VERSION ""

NS_ :

BS_:

BU_:

BO_ 1073 LKAS_ob06_10: 6 Vector__XXX
 SG_ ob_LKA_Disable_Reason : 55|16@0+ (0.01,0) [0|0] "" Vector__XXX
 SG_ ob_LKA_T1_Mon : 39|16@0- (0.01,0) [-327.68|327.67] "" Vector__XXX
 SG_ ob_LKA_SampleTime_Mon : 23|16@0- (0.01,0) [-327.68|327.67] "" Vector__XXX
 SG_ ob_LKA_ExitFlg_Mon : 7|16@0+ (0.01,0) [0|0] "" Vector__XXX

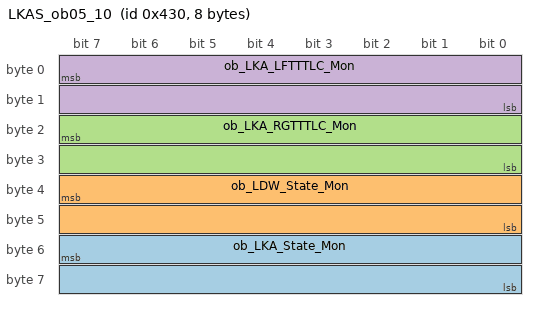
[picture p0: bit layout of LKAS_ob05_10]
BO_ 1072 LKAS_ob05_10: 8 Vector__XXX
 SG_ ob_LKA_State_Mon : 55|16@0+ (0.01,0) [0|0] "" Vector__XXX
 SG_ ob_LDW_State_Mon : 39|16@0+ (0.01,0) [0|0] "" Vector__XXX
 SG_ ob_LKA_RGTTTLC_Mon : 23|16@0- (0.01,0) [-327.68|327.67] "" Vector__XXX
 SG_ ob_LKA_LFTTTLC_Mon : 7|16@0- (0.01,0) [-327.68|327.67] "" Vector__XXX

BA_DEF_  "BusType" STRING ;
BA_DEF_DEF_  "BusType" "CAN";
